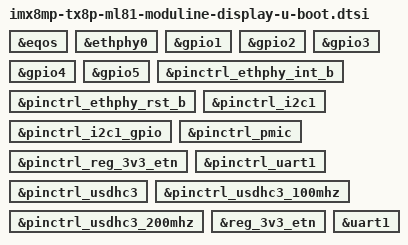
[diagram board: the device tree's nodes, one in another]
// SPDX-License-Identifier: (GPL-2.0 OR MIT)
/*
 * Copyright (C) 2025 Maud Spierings <maudspierings@gocontroll.com>
 */

#include "imx8mp-u-boot.dtsi"

&eqos {
	bootph-pre-ram;
};

&ethphy0 {
	bootph-pre-ram;
};

&gpio1 {
	bootph-pre-ram;
};

&gpio2 {
	bootph-pre-ram;
};

&gpio3 {
	bootph-pre-ram;
};

&gpio4 {
	bootph-pre-ram;
};

&gpio5 {
	bootph-pre-ram;
};

&pinctrl_ethphy_int_b {
	bootph-pre-ram;
};

&pinctrl_ethphy_rst_b {
	bootph-pre-ram;
};

&pinctrl_i2c1 {
	bootph-pre-ram;
};

&pinctrl_i2c1_gpio {
	bootph-pre-ram;
};

&pinctrl_pmic {
	bootph-pre-ram;
};

&pinctrl_reg_3v3_etn {
	bootph-pre-ram;
};

&pinctrl_uart1 {
	bootph-pre-ram;
};

&pinctrl_usdhc3 {
	bootph-pre-ram;
};

&pinctrl_usdhc3_100mhz {
	bootph-pre-ram;
};

&pinctrl_usdhc3_200mhz {
	bootph-pre-ram;
};

&reg_3v3_etn {
	bootph-pre-ram;
};

&uart1 {
	bootph-pre-ram;
};
